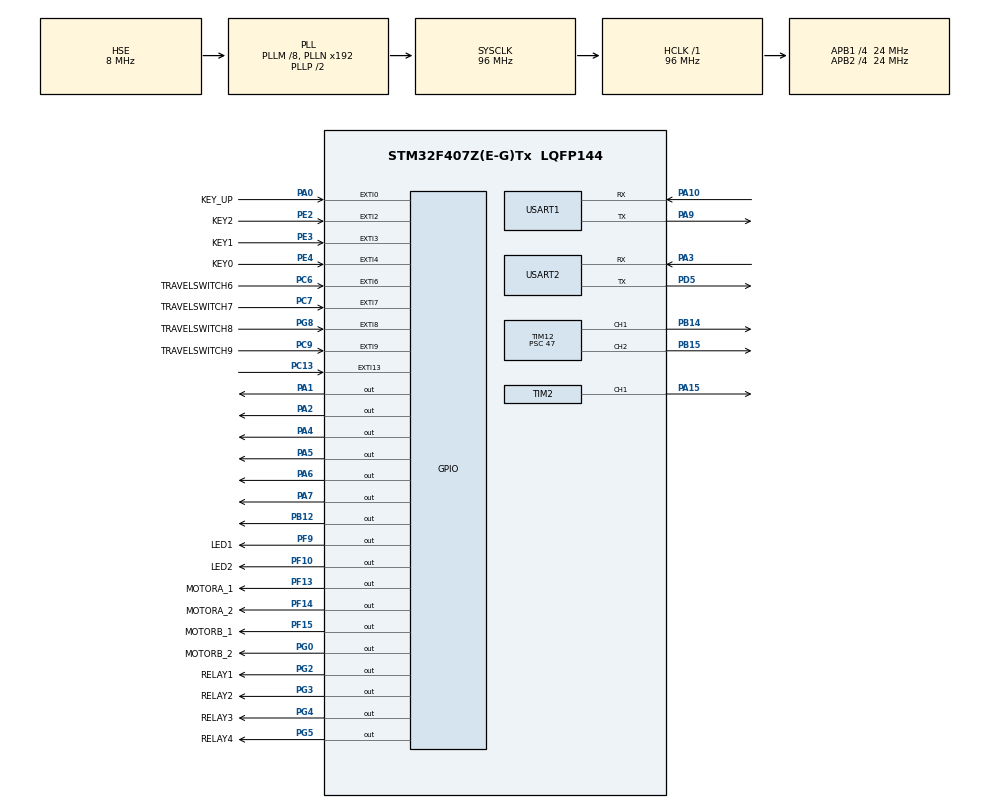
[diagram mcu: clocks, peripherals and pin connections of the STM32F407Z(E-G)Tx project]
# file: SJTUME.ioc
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Dma.Request0=USART1_RX
Dma.USART1_RX.0.Direction=DMA_PERIPH_TO_MEMORY
Dma.USART1_RX.0.FIFOMode=DMA_FIFOMODE_DISABLE
Dma.USART1_RX.0.Instance=DMA2_Stream2
Dma.USART1_RX.0.MemDataAlignment=DMA_MDATAALIGN_BYTE
Dma.USART1_RX.0.MemInc=DMA_MINC_ENABLE
Dma.USART1_RX.0.Mode=DMA_NORMAL
Dma.USART1_RX.0.PeriphDataAlignment=DMA_PDATAALIGN_BYTE
Dma.USART1_RX.0.PeriphInc=DMA_PINC_DISABLE
Dma.USART1_RX.0.Priority=DMA_PRIORITY_LOW
Mcu.Family=STM32F4
Mcu.Name=STM32F407Z(E-G)Tx
Mcu.Package=LQFP144
NVIC.DMA2_Stream2_IRQn=true\:0\:0\:false\:false\:true
NVIC.EXTI0_IRQn=true\:5\:0\:true\:false\:true
NVIC.EXTI15_10_IRQn=true\:5\:0\:true\:false\:true
NVIC.EXTI2_IRQn=true\:5\:0\:true\:false\:true
NVIC.EXTI3_IRQn=true\:5\:0\:true\:false\:true
NVIC.EXTI4_IRQn=true\:5\:0\:true\:false\:true
NVIC.EXTI9_5_IRQn=true\:5\:0\:true\:false\:true
NVIC.PriorityGroup=NVIC_PRIORITYGROUP_4
NVIC.TIM1_UP_TIM10_IRQn=true\:0\:0\:false\:false\:true
NVIC.TIM3_IRQn=true\:1\:0\:true\:false\:true
NVIC.TIM4_IRQn=true\:1\:0\:true\:false\:true
NVIC.TIM5_IRQn=true\:1\:0\:true\:false\:true
NVIC.USART1_IRQn=true\:5\:0\:true\:false\:true
PA0-WKUP.GPIO_Label=KEY_UP
PA0-WKUP.GPIO_ModeDefaultEXTI=GPIO_MODE_IT_RISING
PA0-WKUP.GPIO_PuPd=GPIO_PULLDOWN
PA0-WKUP.Signal=GPXTI0
PA1.GPIO_ModeDefaultOutputPP=GPIO_MODE_OUTPUT_PP
PA1.GPIO_PuPd=GPIO_PULLUP
PA1.GPIO_Speed=GPIO_SPEED_FREQ_HIGH
PA1.PinState=GPIO_PIN_RESET
PA1.Signal=GPIO_Output
PA10.Mode=Asynchronous
PA10.Signal=USART1_RX
PA15.Signal=S_TIM2_CH1_ETR
PA2.GPIO_ModeDefaultOutputPP=GPIO_MODE_OUTPUT_PP
PA2.GPIO_PuPd=GPIO_PULLUP
PA2.GPIO_Speed=GPIO_SPEED_FREQ_VERY_HIGH
PA2.PinState=GPIO_PIN_RESET
PA2.Signal=GPIO_Output
PA3.Mode=Asynchronous
PA3.Signal=USART2_RX
PA4.GPIO_ModeDefaultOutputPP=GPIO_MODE_OUTPUT_PP
PA4.GPIO_PuPd=GPIO_PULLUP
PA4.GPIO_Speed=GPIO_SPEED_FREQ_HIGH
PA4.PinState=GPIO_PIN_RESET
PA4.Signal=GPIO_Output
PA5.GPIO_ModeDefaultOutputPP=GPIO_MODE_OUTPUT_PP
PA5.GPIO_PuPd=GPIO_PULLUP
PA5.GPIO_Speed=GPIO_SPEED_FREQ_HIGH
PA5.PinState=GPIO_PIN_RESET
PA5.Signal=GPIO_Output
PA6.GPIO_ModeDefaultOutputPP=GPIO_MODE_OUTPUT_PP
PA6.GPIO_PuPd=GPIO_PULLUP
PA6.GPIO_Speed=GPIO_SPEED_FREQ_HIGH
PA6.PinState=GPIO_PIN_RESET
PA6.Signal=GPIO_Output
PA7.GPIO_ModeDefaultOutputPP=GPIO_MODE_OUTPUT_PP
PA7.GPIO_PuPd=GPIO_PULLUP
PA7.GPIO_Speed=GPIO_SPEED_FREQ_VERY_HIGH
PA7.PinState=GPIO_PIN_RESET
PA7.Signal=GPIO_Output
PA9.Mode=Asynchronous
PA9.Signal=USART1_TX
PB12.GPIO_PuPd=GPIO_PULLUP
PB12.PinState=GPIO_PIN_SET
PB12.Signal=GPIO_Output
PB14.Signal=S_TIM12_CH1
PB15.Signal=S_TIM12_CH2
PC13-ANTI_TAMP.GPIO_ModeDefaultEXTI=GPIO_MODE_IT_FALLING
PC13-ANTI_TAMP.GPIO_PuPd=GPIO_PULLUP
PC13-ANTI_TAMP.Signal=GPXTI13
PC6.GPIO_Label=TRAVELSWITCH6
PC6.GPIO_ModeDefaultEXTI=GPIO_MODE_IT_FALLING
PC6.GPIO_PuPd=GPIO_PULLUP
PC6.Signal=GPXTI6
PC7.GPIO_Label=TRAVELSWITCH7
PC7.GPIO_ModeDefaultEXTI=GPIO_MODE_IT_FALLING
PC7.GPIO_PuPd=GPIO_PULLUP
PC7.Signal=GPXTI7
PC9.GPIO_Label=TRAVELSWITCH9
PC9.GPIO_ModeDefaultEXTI=GPIO_MODE_IT_FALLING
PC9.GPIO_PuPd=GPIO_PULLUP
PC9.Signal=GPXTI9
PD5.Mode=Asynchronous
PD5.Signal=USART2_TX
PE2.GPIO_Label=KEY2
PE2.GPIO_ModeDefaultEXTI=GPIO_MODE_IT_FALLING
PE2.GPIO_PuPd=GPIO_PULLUP
PE2.Signal=GPXTI2
PE3.GPIO_Label=KEY1
PE3.GPIO_ModeDefaultEXTI=GPIO_MODE_IT_FALLING
PE3.GPIO_PuPd=GPIO_PULLUP
PE3.Signal=GPXTI3
PE4.GPIO_Label=KEY0
PE4.GPIO_ModeDefaultEXTI=GPIO_MODE_IT_FALLING
PE4.GPIO_PuPd=GPIO_PULLUP
PE4.Signal=GPXTI4
PF10.GPIO_Label=LED2
PF10.GPIO_ModeDefaultOutputPP=GPIO_MODE_OUTPUT_PP
PF10.GPIO_PuPd=GPIO_PULLUP
PF10.Signal=GPIO_Output
PF13.GPIO_Label=MOTORA_1
PF13.GPIO_ModeDefaultOutputPP=GPIO_MODE_OUTPUT_PP
PF13.GPIO_PuPd=GPIO_PULLUP
PF13.GPIO_Speed=GPIO_SPEED_FREQ_MEDIUM
PF13.PinState=GPIO_PIN_RESET
PF13.Signal=GPIO_Output
PF14.GPIO_Label=MOTORA_2
PF14.GPIO_ModeDefaultOutputPP=GPIO_MODE_OUTPUT_PP
PF14.GPIO_PuPd=GPIO_PULLUP
PF14.GPIO_Speed=GPIO_SPEED_FREQ_MEDIUM
PF14.PinState=GPIO_PIN_RESET
PF14.Signal=GPIO_Output
PF15.GPIO_Label=MOTORB_1
PF15.GPIO_ModeDefaultOutputPP=GPIO_MODE_OUTPUT_PP
PF15.GPIO_PuPd=GPIO_PULLUP
PF15.GPIO_Speed=GPIO_SPEED_FREQ_MEDIUM
PF15.PinState=GPIO_PIN_RESET
PF15.Signal=GPIO_Output
PF9.GPIO_Label=LED1
PF9.GPIO_PuPd=GPIO_PULLUP
PF9.PinState=GPIO_PIN_SET
PF9.Signal=GPIO_Output
PG0.GPIO_Label=MOTORB_2
PG0.GPIO_ModeDefaultOutputPP=GPIO_MODE_OUTPUT_PP
PG0.GPIO_PuPd=GPIO_PULLUP
PG0.GPIO_Speed=GPIO_SPEED_FREQ_MEDIUM
PG0.PinState=GPIO_PIN_RESET
PG0.Signal=GPIO_Output
PG2.GPIO_Label=RELAY1
PG2.GPIO_ModeDefaultOutputPP=GPIO_MODE_OUTPUT_PP
PG2.GPIO_PuPd=GPIO_PULLUP
PG2.GPIO_Speed=GPIO_SPEED_FREQ_MEDIUM
PG2.PinState=GPIO_PIN_RESET
PG2.Signal=GPIO_Output
PG3.GPIO_Label=RELAY2
PG3.GPIO_ModeDefaultOutputPP=GPIO_MODE_OUTPUT_PP
PG3.GPIO_PuPd=GPIO_PULLUP
PG3.GPIO_Speed=GPIO_SPEED_FREQ_MEDIUM
PG3.PinState=GPIO_PIN_RESET
PG3.Signal=GPIO_Output
PG4.GPIO_Label=RELAY3
PG4.GPIO_ModeDefaultOutputPP=GPIO_MODE_OUTPUT_PP
PG4.GPIO_PuPd=GPIO_PULLUP
PG4.GPIO_Speed=GPIO_SPEED_FREQ_MEDIUM
PG4.PinState=GPIO_PIN_RESET
PG4.Signal=GPIO_Output
PG5.GPIO_Label=RELAY4
PG5.GPIO_ModeDefaultOutputPP=GPIO_MODE_OUTPUT_PP
PG5.GPIO_PuPd=GPIO_PULLUP
PG5.GPIO_Speed=GPIO_SPEED_FREQ_MEDIUM
PG5.PinState=GPIO_PIN_RESET
PG5.Signal=GPIO_Output
PG8.GPIO_Label=TRAVELSWITCH8
PG8.GPIO_ModeDefaultEXTI=GPIO_MODE_IT_FALLING
PG8.GPIO_PuPd=GPIO_PULLUP
PG8.Signal=GPXTI8
PH0-OSC_IN.Mode=HSE-External-Oscillator
PH0-OSC_IN.Signal=RCC_OSC_IN
PH1-OSC_OUT.Mode=HSE-External-Oscillator
PH1-OSC_OUT.Signal=RCC_OSC_OUT
ProjectManager.HeapSize=0x200
ProjectManager.StackSize=0x400
ProjectManager.TargetToolchain=MDK-ARM V5
RCC.48MHZClocksFreq_Value=48000000
RCC.AHBFreq_Value=96000000
RCC.APB1CLKDivider=RCC_HCLK_DIV4
RCC.APB1Freq_Value=24000000
RCC.APB1TimFreq_Value=48000000
RCC.APB2CLKDivider=RCC_HCLK_DIV4
RCC.APB2Freq_Value=24000000
RCC.APB2TimFreq_Value=48000000
RCC.CortexFreq_Value=96000000
RCC.HCLKFreq_Value=96000000
RCC.HSE_VALUE=8000000
RCC.HSI_VALUE=16000000
RCC.LSE_VALUE=32768
RCC.PLLM=8
RCC.PLLSourceVirtual=RCC_PLLSOURCE_HSE
RCC.SYSCLKFreq_VALUE=96000000
RCC.SYSCLKSource=RCC_SYSCLKSOURCE_PLLCLK
RCC.VCOOutputFreq_Value=192000000
SH.S_TIM12_CH1.0=TIM12_CH1,PWM Generation1 CH1
SH.S_TIM12_CH2.0=TIM12_CH2,PWM Generation2 CH2
SH.S_TIM2_CH1_ETR.0=TIM2_CH1,PWM Generation1 CH1
TIM10.Period=59
TIM10.Prescaler=999
TIM12.Channel-PWM\ Generation1\ CH1=TIM_CHANNEL_1
TIM12.Channel-PWM\ Generation2\ CH2=TIM_CHANNEL_2
TIM12.Period=19000
TIM12.Prescaler=47
TIM2.Channel-PWM\ Generation1\ CH1=TIM_CHANNEL_1
TIM2.Period=19000
TIM2.Prescaler=47
TIM3.Period=59
TIM3.Prescaler=999
TIM4.Period=200-1
TIM4.Prescaler=4800-1
TIM5.Period=59
TIM5.Prescaler=999
USART1.VirtualMode=VM_ASYNC
USART2.VirtualMode=VM_ASYNC
VP_TIM10_VS_ClockSourceINT.Mode=Enable_Timer
VP_TIM12_VS_ClockSourceINT.Mode=Internal
VP_TIM2_VS_ClockSourceINT.Mode=Internal
VP_TIM3_VS_ClockSourceINT.Mode=Internal
VP_TIM4_VS_ClockSourceINT.Mode=Internal
VP_TIM5_VS_ClockSourceINT.Mode=Internal
board=SJTUME

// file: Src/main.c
/**
  ******************************************************************************
  * File Name          : main.c
  * Description        : Main program body
  ******************************************************************************
  ** This notice applies to any and all portions of this file
  * that are not between comment pairs USER CODE BEGIN and
  * USER CODE END. Other portions of this file, whether
  * inserted by the user or by software development tools
  * are owned by their respective copyright owners.
  *
  * COPYRIGHT(c) 2017 STMicroelectronics
  *
  * Redistribution and use in source and binary forms, with or without modification,
  * are permitted provided that the following conditions are met:
  *   1. Redistributions of source code must retain the above copyright notice,
  *      this list of conditions and the following disclaimer.
  *   2. Redistributions in binary form must reproduce the above copyright notice,
  *      this list of conditions and the following disclaimer in the documentation
  *      and/or other materials provided with the distribution.
  *   3. Neither the name of STMicroelectronics nor the names of its contributors
  *      may be used to endorse or promote products derived from this software
  *      without specific prior written permission.
  *
  * THIS SOFTWARE IS PROVIDED BY THE COPYRIGHT HOLDERS AND CONTRIBUTORS "AS IS"
  * AND ANY EXPRESS OR IMPLIED WARRANTIES, INCLUDING, BUT NOT LIMITED TO, THE
  * IMPLIED WARRANTIES OF MERCHANTABILITY AND FITNESS FOR A PARTICULAR PURPOSE ARE
  * DISCLAIMED. IN NO EVENT SHALL THE COPYRIGHT HOLDER OR CONTRIBUTORS BE LIABLE
  * FOR ANY DIRECT, INDIRECT, INCIDENTAL, SPECIAL, EXEMPLARY, OR CONSEQUENTIAL
  * DAMAGES (INCLUDING, BUT NOT LIMITED TO, PROCUREMENT OF SUBSTITUTE GOODS OR
  * SERVICES; LOSS OF USE, DATA, OR PROFITS; OR BUSINESS INTERRUPTION) HOWEVER
  * CAUSED AND ON ANY THEORY OF LIABILITY, WHETHER IN CONTRACT, STRICT LIABILITY,
  * OR TORT (INCLUDING NEGLIGENCE OR OTHERWISE) ARISING IN ANY WAY OUT OF THE USE
  * OF THIS SOFTWARE, EVEN IF ADVISED OF THE POSSIBILITY OF SUCH DAMAGE.
  *
  ******************************************************************************
  */
#include "main.h"
#include "stm32f4xx_hal.h"
#include "dma.h"
#include "tim.h"
#include "usart.h"
#include "gpio.h"

/* USER CODE BEGIN Includes */
#include "drivers_debuguart.h"
#include "utilities_debug.h"
#include "peripheral_define.h"
#include "pwm_server_motor.h"
/* USER CODE END Includes */

/* USER CODE BEGIN PV */
/* Private variables ---------------------------------------------------------*/

/* USER CODE END PV */

void SystemClock_Config(void);

/* USER CODE BEGIN PFP */
/* Private function prototypes -----------------------------------------------*/

/* USER CODE END PFP */

/* USER CODE BEGIN 0 */
int timer_count = 0;
/* USER CODE END 0 */

int main(void)
{

  /* MCU Configuration----------------------------------------------------------*/

  /* Reset of all peripherals, Initializes the Flash interface and the Systick. */
  HAL_Init();

  /* Configure the system clock */
  SystemClock_Config();

  /* Initialize all configured peripherals */
  MX_GPIO_Init();
  MX_DMA_Init();
  MX_USART2_UART_Init();
  MX_USART1_UART_Init();
  MX_TIM2_Init();
  MX_TIM12_Init();
  MX_TIM3_Init();
  MX_TIM4_Init();
  MX_TIM10_Init();
  MX_TIM5_Init();

  /* USER CODE BEGIN 2 */
	InitDebugUart();
	InitServerMotors();
	HAL_TIM_Base_Start_IT(&htim4);
  /* USER CODE END 2 */

  /* Infinite loop */
  while (1)
  {

  /* USER CODE BEGIN 3 */
//0.0
		if(timer_count == 50)
		{
			HAL_GPIO_TogglePin(LED1_GPIO_Port, LED1_Pin);
			timer_count = 0;
		}

  }
  /* USER CODE END 3 */

}

/** System Clock Configuration
*/
void SystemClock_Config(void)
{

  RCC_OscInitTypeDef RCC_OscInitStruct;
  RCC_ClkInitTypeDef RCC_ClkInitStruct;

    /**Configure the main internal regulator output voltage
    */
  __HAL_RCC_PWR_CLK_ENABLE();

  __HAL_PWR_VOLTAGESCALING_CONFIG(PWR_REGULATOR_VOLTAGE_SCALE1);

    /**Initializes the CPU, AHB and APB busses clocks
    */
  RCC_OscInitStruct.OscillatorType = RCC_OSCILLATORTYPE_HSE;
  RCC_OscInitStruct.HSEState = RCC_HSE_ON;
  RCC_OscInitStruct.PLL.PLLState = RCC_PLL_ON;
  RCC_OscInitStruct.PLL.PLLSource = RCC_PLLSOURCE_HSE;
  RCC_OscInitStruct.PLL.PLLM = 8;
  RCC_OscInitStruct.PLL.PLLN = 192;
  RCC_OscInitStruct.PLL.PLLP = RCC_PLLP_DIV2;
  RCC_OscInitStruct.PLL.PLLQ = 4;
  if (HAL_RCC_OscConfig(&RCC_OscInitStruct) != HAL_OK)
  {
    _Error_Handler(__FILE__, __LINE__);
  }

    /**Initializes the CPU, AHB and APB busses clocks
    */
  RCC_ClkInitStruct.ClockType = RCC_CLOCKTYPE_HCLK|RCC_CLOCKTYPE_SYSCLK
                              |RCC_CLOCKTYPE_PCLK1|RCC_CLOCKTYPE_PCLK2;
  RCC_ClkInitStruct.SYSCLKSource = RCC_SYSCLKSOURCE_PLLCLK;
  RCC_ClkInitStruct.AHBCLKDivider = RCC_SYSCLK_DIV1;
  RCC_ClkInitStruct.APB1CLKDivider = RCC_HCLK_DIV4;
  RCC_ClkInitStruct.APB2CLKDivider = RCC_HCLK_DIV4;

  if (HAL_RCC_ClockConfig(&RCC_ClkInitStruct, FLASH_LATENCY_3) != HAL_OK)
  {
    _Error_Handler(__FILE__, __LINE__);
  }

    /**Configure the Systick interrupt time
    */
  HAL_SYSTICK_Config(HAL_RCC_GetHCLKFreq()/1000);

    /**Configure the Systick
    */
  HAL_SYSTICK_CLKSourceConfig(SYSTICK_CLKSOURCE_HCLK);

  /* SysTick_IRQn interrupt configuration */
  HAL_NVIC_SetPriority(SysTick_IRQn, 0, 0);
}

void _Error_Handler(char * file, int line)
{
  /* USER CODE BEGIN Error_Handler_Debug */
  /* User can add his own implementation to report the HAL error return state */
  while(1)
  {
		fw_printfln("Error Handler");
		fw_printf("%s(%d): \r\n", file, line);
		HAL_Delay(1000);
  }
  /* USER CODE END Error_Handler_Debug */
}

/************************ (C) COPYRIGHT STMicroelectronics *****END OF FILE****/
